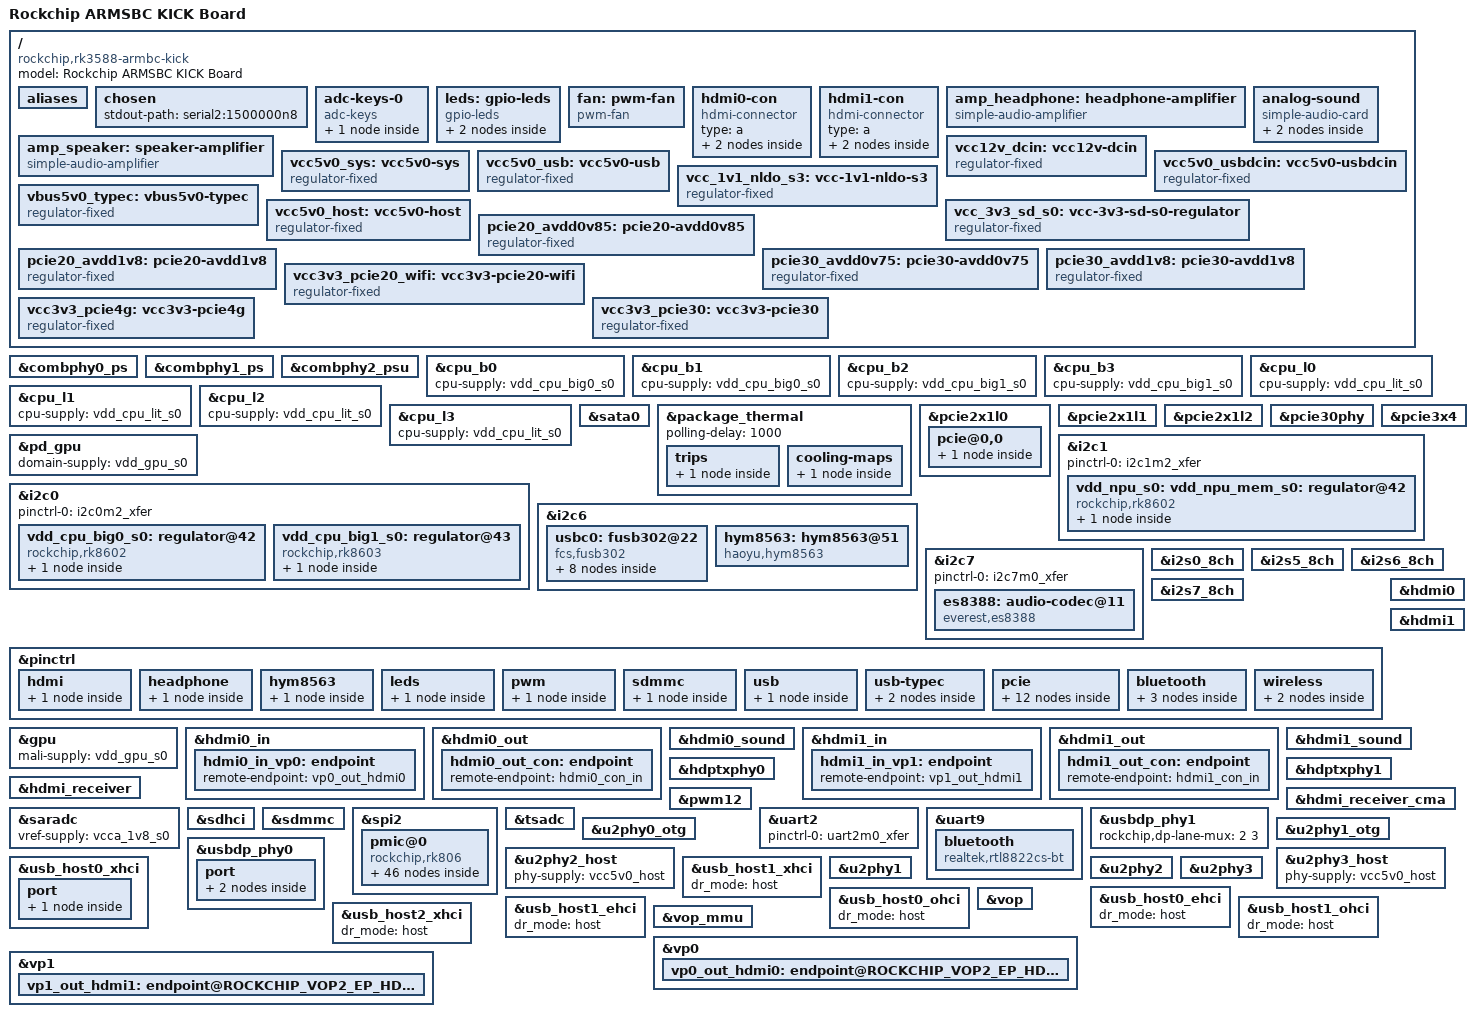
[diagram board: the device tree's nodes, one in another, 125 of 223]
// SPDX-License-Identifier: (GPL-2.0+ OR MIT)
/*
 * Copyright (c) 2024 Rockchip Electronics Co., Ltd.
 *
 */

/dts-v1/;

#include <dt-bindings/gpio/gpio.h>
#include <dt-bindings/input/input.h>
#include <dt-bindings/pinctrl/rockchip.h>
#include <dt-bindings/soc/rockchip,vop2.h>
#include <dt-bindings/usb/pd.h>
#include "rk3588.dtsi"

/ {
	model = "Rockchip ARMSBC KICK Board";
	compatible = "rockchip,rk3588-armbc-kick", "rockchip,rk3588";

	aliases {
		mmc0 = &sdhci;
		mmc1 = &sdmmc;
	};

	chosen {
		stdout-path = "serial2:1500000n8";
	};
	
	adc-keys-0 {
		compatible = "adc-keys";
		io-channels = <&saradc 1>;
		io-channel-names = "buttons";
		keyup-threshold-microvolt = <1800000>;
		poll-interval = <100>;

		button-recovery {
			label = "Recovery";
			linux,code = <KEY_VENDOR>;
			press-threshold-microvolt = <2000>;
		};
	};
	
	leds: gpio-leds {
		compatible = "gpio-leds";
		pinctrl-names = "default";
		status = "okay";
 
		system_led@1 {
			gpios = <&gpio3 RK_PB7 GPIO_ACTIVE_HIGH>;
			linux,default-trigger = "heartbeat";
			linux,default-trigger-delay-ms = <0>;
		};
		
		work_led {
			gpios = <&gpio1 RK_PA4 GPIO_ACTIVE_HIGH>;
			pinctrl-0 = <&work_leds_gpio>;
			default-state = "on";
		};
	};
	
	fan: pwm-fan {
		compatible = "pwm-fan";
		cooling-levels = <0 80 160 255>; // Simple 3-level control
		fan-supply = <&vcc5v0_sys>;      // Replace with correct regulator if needed
		pwms = <&pwm12 0 50000 0>;       // 50 kHz, active high
		#cooling-cells = <2>;
		pinctrl-names = "default";
		pinctrl-0 = <&pwm12_pins>;
	};

	hdmi0-con {
		compatible = "hdmi-connector";
		type = "a";

		port {
			hdmi0_con_in: endpoint {
				remote-endpoint = <&hdmi0_out_con>;
			};
		};
	};

	hdmi1-con {
		compatible = "hdmi-connector";
		type = "a";

		port {
			hdmi1_con_in: endpoint {
				remote-endpoint = <&hdmi1_out_con>;
			};
		};
	};

	
	amp_headphone: headphone-amplifier {
		compatible = "simple-audio-amplifier";
		enable-gpios = <&gpio2 RK_PB3 GPIO_ACTIVE_HIGH>;
		pinctrl-names = "default";
		//pinctrl-0 = <&headphone_amplifier_en>;
		sound-name-prefix = "Headphones Amplifier";
	};

	amp_speaker: speaker-amplifier {
		compatible = "simple-audio-amplifier";
		enable-gpios = <&gpio2 RK_PB2 GPIO_ACTIVE_HIGH>;
		pinctrl-names = "default";
		//pinctrl-0 = <&speaker_amplifier_en>;
		sound-name-prefix = "Speaker Amplifier";
	};
	
	analog-sound {
		compatible = "simple-audio-card";
		pinctrl-names = "default";
		pinctrl-0 = <&hp_detect>;
		simple-audio-card,name = "RK3588 EVB1 Audio";
		simple-audio-card,aux-devs = <&amp_headphone>, <&amp_speaker>;
		simple-audio-card,bitclock-master = <&masterdai>;
		simple-audio-card,format = "i2s";
		simple-audio-card,frame-master = <&masterdai>;
		simple-audio-card,hp-det-gpios = <&gpio1 RK_PD5 GPIO_ACTIVE_LOW>;
		simple-audio-card,mclk-fs = <256>;
		simple-audio-card,pin-switches = "Headphones", "Speaker";
		simple-audio-card,routing =
			"Speaker Amplifier INL", "LOUT2",
			"Speaker Amplifier INR", "ROUT2",
			"Speaker", "Speaker Amplifier OUTL",
			"Speaker", "Speaker Amplifier OUTR",
			"Headphones Amplifier INL", "LOUT1",
			"Headphones Amplifier INR", "ROUT1",
			"Headphones", "Headphones Amplifier OUTL",
			"Headphones", "Headphones Amplifier OUTR",
			"LINPUT1", "Onboard Microphone",
			"RINPUT1", "Onboard Microphone",
			"LINPUT2", "Microphone Jack",
			"RINPUT2", "Microphone Jack";
		simple-audio-card,widgets =
			"Microphone", "Microphone Jack",
			"Microphone", "Onboard Microphone",
			"Headphone", "Headphones",
			"Speaker", "Speaker";

		simple-audio-card,cpu {
			sound-dai = <&i2s0_8ch>;
		};

		masterdai: simple-audio-card,codec {
			sound-dai = <&es8388>;		
		};
	};
		
	vcc12v_dcin: vcc12v-dcin {
		compatible = "regulator-fixed";
		regulator-name = "vcc12v_dcin";
		regulator-always-on;
		regulator-boot-on;
		regulator-min-microvolt = <12000000>;
		regulator-max-microvolt = <12000000>;
	};

	vcc5v0_sys: vcc5v0-sys {
		compatible = "regulator-fixed";
		regulator-name = "vcc5v0_sys";
		regulator-always-on;
		regulator-boot-on;
		regulator-min-microvolt = <5000000>;
		regulator-max-microvolt = <5000000>;
		vin-supply = <&vcc12v_dcin>;
	};

	vcc5v0_usbdcin: vcc5v0-usbdcin {
		compatible = "regulator-fixed";
		regulator-name = "vcc5v0_usbdcin";
		regulator-always-on;
		regulator-boot-on;
		regulator-min-microvolt = <5000000>;
		regulator-max-microvolt = <5000000>;
		vin-supply = <&vcc12v_dcin>;
	};

	vcc5v0_usb: vcc5v0-usb {
		compatible = "regulator-fixed";
		regulator-name = "vcc5v0_usb";
		regulator-always-on;
		regulator-boot-on;
		regulator-min-microvolt = <5000000>;
		regulator-max-microvolt = <5000000>;
		vin-supply = <&vcc5v0_usbdcin>;
	};
	
	vcc_1v1_nldo_s3: vcc-1v1-nldo-s3 {
		compatible = "regulator-fixed";
		regulator-name = "vcc_1v1_nldo_s3";
		regulator-always-on;
		regulator-boot-on;
		regulator-min-microvolt = <1100000>;
		regulator-max-microvolt = <1100000>;
		vin-supply = <&vcc5v0_sys>;
	};

	vbus5v0_typec: vbus5v0-typec {
		compatible = "regulator-fixed";
		regulator-name = "vbus5v0_typec";
		regulator-min-microvolt = <5000000>;
		regulator-max-microvolt = <5000000>;
		enable-active-high;
		gpio = <&gpio3 RK_PB0 GPIO_ACTIVE_HIGH>;
		vin-supply = <&vcc5v0_usb>;
		pinctrl-names = "default";
		pinctrl-0 = <&typec5v_pwren>;
	};

	vcc5v0_host: vcc5v0-host {
		compatible = "regulator-fixed";
		regulator-name = "vcc5v0_host";
		regulator-boot-on;
		regulator-always-on;
		regulator-min-microvolt = <5000000>;
		regulator-max-microvolt = <5000000>;
		enable-active-high;
		gpio = <&gpio3 RK_PA4 GPIO_ACTIVE_HIGH>;
		vin-supply = <&vcc5v0_usb>;
		pinctrl-names = "default";
		pinctrl-0 = <&vcc5v0_host_en>;
	};

	vcc_3v3_sd_s0: vcc-3v3-sd-s0-regulator {
		compatible = "regulator-fixed";
		regulator-name = "vcc_3v3_sd_s0";
		#regulator-boot-on;
		#regulator-always-on;
		gpio = <&gpio0 RK_PB7 GPIO_ACTIVE_HIGH>;  
		enable-active-high;
		pinctrl-names = "default";
		pinctrl-0 = <&sd_s0_pwr>;
	};
	
	pcie20_avdd0v85: pcie20-avdd0v85 {
		compatible = "regulator-fixed";
		regulator-name = "pcie20_avdd0v85";
		regulator-boot-on;
		regulator-always-on;
		regulator-min-microvolt = <850000>;
		regulator-max-microvolt = <850000>;
		vin-supply = <&vdda_0v85_s0>;
	};

	pcie20_avdd1v8: pcie20-avdd1v8 {
		compatible = "regulator-fixed";
		regulator-name = "pcie20_avdd1v8";
		regulator-boot-on;
		regulator-always-on;
		regulator-min-microvolt = <1800000>;
		regulator-max-microvolt = <1800000>;
		vin-supply = <&vcca_1v8_s0>;
	};

	pcie30_avdd0v75: pcie30-avdd0v75 {
		compatible = "regulator-fixed";
		regulator-name = "pcie30_avdd0v75";
		regulator-boot-on;
		regulator-always-on;
		regulator-min-microvolt = <750000>;
		regulator-max-microvolt = <750000>;
		vin-supply = <&vdda_0v75_s0>;
	};

	pcie30_avdd1v8: pcie30-avdd1v8 {
		compatible = "regulator-fixed";
		regulator-name = "pcie30_avdd1v8";
		regulator-boot-on;
		regulator-always-on;
		regulator-min-microvolt = <1800000>;
		regulator-max-microvolt = <1800000>;
		vin-supply = <&vcca_1v8_s0>;
	};

	vcc3v3_pcie20_wifi: vcc3v3-pcie20-wifi {
		compatible = "regulator-fixed";
		regulator-name = "vcc3v3_pcie20_wifi";
		regulator-min-microvolt = <3300000>;
		regulator-max-microvolt = <3300000>;
		gpios = <&gpio0 RK_PC4 GPIO_ACTIVE_HIGH>;
		enable-active-high;
		pinctrl-0 = <&wifi_power_en>;
		startup-delay-us = <5000>;
		vin-supply = <&vcc12v_dcin>;
	};

	vcc3v3_pcie4g: vcc3v3-pcie4g {
		compatible = "regulator-fixed";
		regulator-name = "vcc3v3_pcie4g";
		regulator-min-microvolt = <3300000>;
		regulator-max-microvolt = <3300000>;
		enable-active-high;
		gpios = <&gpio2 RK_PC5 GPIO_ACTIVE_HIGH>;
		vin-supply = <&vcc12v_dcin>;
		regulator-boot-on;
		regulator-always-on;
	};

	vcc3v3_pcie30: vcc3v3-pcie30 {
		compatible = "regulator-fixed";
		regulator-name = "vcc3v3_pcie30";
		regulator-min-microvolt = <3300000>;
		regulator-max-microvolt = <3300000>;
		enable-active-high;
		startup-delay-us = <5000>;
		vin-supply = <&vcc12v_dcin>;
	};
};

&combphy0_ps {
	status = "okay";
};

&combphy1_ps {
	status = "okay";
};

&combphy2_psu {
	status = "okay";
};

&cpu_b0 {
	cpu-supply = <&vdd_cpu_big0_s0>;
};

&cpu_b1 {
	cpu-supply = <&vdd_cpu_big0_s0>;
};

&cpu_b2 {
	cpu-supply = <&vdd_cpu_big1_s0>;
};

&cpu_b3 {
	cpu-supply = <&vdd_cpu_big1_s0>;
};

&cpu_l0 {
	cpu-supply = <&vdd_cpu_lit_s0>;
};

&cpu_l1 {
	cpu-supply = <&vdd_cpu_lit_s0>;
};

&cpu_l2 {
	cpu-supply = <&vdd_cpu_lit_s0>;
};

&cpu_l3 {
	cpu-supply = <&vdd_cpu_lit_s0>;
};

&sata0 {
	status = "okay";
};

&package_thermal {
    polling-delay = <1000>;

    trips {
        cpu_fan_trip: cpu-fan-trip {
            temperature = <60000>;   // 60°C
            hysteresis = <2000>;
            type = "active";
        };
    };

    cooling-maps {
        map0 {
            trip = <&cpu_fan_trip>;
            cooling-device = <&fan 0 2>;  // Fan duty levels (0–2 from your cooling-levels)
        };
    };
};

&pcie2x1l0 {
        reset-gpios = <&gpio4 RK_PA5 GPIO_ACTIVE_HIGH>;
        pinctrl-names = "default";
        vpcie3v3-supply = <&vcc3v3_pcie20_wifi>;
        pinctrl-0 = <&pcie2x1l0_reset>, <&pcie2x1l0_wake>, <&pcie2x1l0_clk>, <&wifi_host_wake_irq>;
        rockchip,skip-scan-in-resume;
        rockchip,perst-inactive-ms = <500>;
        status = "okay";
        
	pcie@0,0 {
		reg = <0x200000 0 0 0 0>;
		#address-cells = <3>;
		#size-cells = <2>;
		ranges;
		device_type = "pci";
		bus-range = <0x20 0x2f>;

		wifi: wifi@0,0 {
			compatible = "pci14e4,449d";
			reg = <0x210000 0 0 0 0>;
			clocks = <&hym8563>;
			clock-names = "lpo";
		};
	};
};

&pcie2x1l1 {
	reset-gpios = <&gpio4 RK_PA2 GPIO_ACTIVE_HIGH>;
	pinctrl-names = "default";
	pinctrl-0 = <&pcie2x1l1_reset>, <&pcie2x1l1_clk>, <&pcie2x1l1_wake>;
	status = "okay";
};

&pcie2x1l2 {
	reset-gpios = <&gpio4 RK_PB0 GPIO_ACTIVE_HIGH>;
	pinctrl-names = "default";
	pinctrl-0 = <&pcie2x1l2_reset>, <&pcie2x1l2_clk>, <&pcie2x1l2_wake>;
	status = "okay";
};

&pcie30phy {
	status = "okay";
};

&pcie3x4 {
	reset-gpios = <&gpio4 RK_PB6 GPIO_ACTIVE_HIGH>;
	vpcie3v3-supply = <&vcc3v3_pcie30>;
	pinctrl-names = "default";
	pinctrl-0 = <&pcie30x4_clk>, <&pcie30x4_reset>, <&pcie30x4_wake>;
	status = "okay";
};

&pd_gpu {
	domain-supply = <&vdd_gpu_s0>;
	status = "okay";
};

&i2c0 {
	pinctrl-names = "default";
	pinctrl-0 = <&i2c0m2_xfer>;
	status = "okay";

	vdd_cpu_big0_s0: regulator@42 {
		compatible = "rockchip,rk8602";
		reg = <0x42>;
		fcs,suspend-voltage-selector = <1>;
		regulator-name = "vdd_cpu_big0_s0";
		regulator-always-on;
		regulator-boot-on;
		regulator-min-microvolt = <550000>;
		regulator-max-microvolt = <1050000>;
		regulator-ramp-delay = <2300>;
		vin-supply = <&vcc5v0_sys>;

		regulator-state-mem {
			regulator-off-in-suspend;
		};
	};

	vdd_cpu_big1_s0: regulator@43 {
		compatible = "rockchip,rk8603", "rockchip,rk8602";
		reg = <0x43>;
		fcs,suspend-voltage-selector = <1>;
		regulator-name = "vdd_cpu_big1_s0";
		regulator-always-on;
		regulator-boot-on;
		regulator-min-microvolt = <550000>;
		regulator-max-microvolt = <1050000>;
		regulator-ramp-delay = <2300>;
		vin-supply = <&vcc5v0_sys>;

		regulator-state-mem {
			regulator-off-in-suspend;
		};
	};
};

&i2c1 {
	pinctrl-names = "default";
	pinctrl-0 = <&i2c1m2_xfer>;
	status = "okay";

	vdd_npu_s0: vdd_npu_mem_s0: regulator@42 {
		compatible = "rockchip,rk8602";
		reg = <0x42>;
		fcs,suspend-voltage-selector = <1>;
		regulator-always-on;
		regulator-boot-on;
		regulator-min-microvolt = <550000>;
		regulator-max-microvolt = <950000>;
		regulator-name = "vdd_npu_s0";
		regulator-ramp-delay = <2300>;
		vin-supply = <&vcc5v0_sys>;

		regulator-state-mem {
			regulator-off-in-suspend;
		};
	};
};

&i2c6 {
	status = "okay";

	usbc0: fusb302@22 {
		compatible = "fcs,fusb302";
		reg = <0x22>;
		interrupt-parent = <&gpio0>;
		interrupts = <RK_PD3 IRQ_TYPE_LEVEL_LOW>;
		pinctrl-names = "default";
		pinctrl-0 = <&usbc0_int>;
		vbus-supply = <&vbus5v0_typec>;
		status = "okay";

		usb_con: connector {
			compatible = "usb-c-connector";
			label = "USB-C";
			data-role = "dual";
			op-sink-microwatt = <1000000>;
			power-role = "dual";
			sink-pdos =
				<PDO_FIXED(5000, 1000, PDO_FIXED_USB_COMM)>;
			source-pdos =
				<PDO_FIXED(5000, 3000, PDO_FIXED_USB_COMM)>;
			try-power-role = "source";

			ports {
				#address-cells = <1>;
				#size-cells = <0>;

				port@0 {
					reg = <0>;

					usbc0_orien_sw: endpoint {
						remote-endpoint = <&usbdp_phy0_orientation_switch>;
					};
				};

				port@1 {
					reg = <1>;

					usbc0_role_sw: endpoint {
						remote-endpoint = <&dwc3_0_role_switch>;
					};
				};

				port@2 {
					reg = <2>;

					dp_altmode_mux: endpoint {
						remote-endpoint = <&usbdp_phy0_dp_altmode_mux>;
					};
				};
			};
		};
	};

	hym8563: hym8563@51 {
		compatible = "haoyu,hym8563";
		reg = <0x51>;
		#clock-cells = <0>;
		clock-frequency = <32768>;
		clock-output-names = "hym8563";
		pinctrl-names = "default";
		pinctrl-0 = <&hym8563_int>;
		interrupt-parent = <&gpio0>;
		interrupts = <RK_PB0 IRQ_TYPE_LEVEL_LOW>;
		wakeup-source;
	};
};

&i2c7 {
	status = "okay";
	pinctrl-0 = <&i2c7m0_xfer>;
	es8388: audio-codec@11 {
		compatible = "everest,es8388", "everest,es8328";
		reg = <0x11>;
		clocks = <&cru I2S0_8CH_MCLKOUT>;
		assigned-clocks = <&cru I2S0_8CH_MCLKOUT>;
		assigned-clock-rates = <12288000>;
		AVDD-supply = <&vcc_1v8_s0>;
		DVDD-supply = <&vcc_1v8_s0>;
		HPVDD-supply = <&vcca_3v3_s0>;
		PVDD-supply = <&vcca_3v3_s0>;
		#sound-dai-cells = <0>;
	};
};

&i2s0_8ch {
	pinctrl-0 = <&i2s0_lrck
		     &i2s0_mclk
		     &i2s0_sclk
		     &i2s0_sdi0
		     &i2s0_sdo0>;
	status = "okay";
};

&i2s5_8ch {
	status = "okay";
};

&i2s6_8ch {
	status = "okay";
};

&i2s7_8ch {
	status = "okay";
};
	
&pinctrl {

	hdmi {
		hdmirx_det: hdmirx-det {
			rockchip,pins = <1 RK_PD5 RK_FUNC_GPIO &pcfg_pull_up>;
		};
	};

	headphone {
		hp_detect: hp-detect {
			rockchip,pins = <1 RK_PC4 RK_FUNC_GPIO &pcfg_pull_none>;
		};
	};

	hym8563 {
		hym8563_int: hym8563-int {
			rockchip,pins = <0 RK_PB0 RK_FUNC_GPIO &pcfg_pull_up>;
		};
	};

	leds {
		work_leds_gpio: work-leds-gpio {
			rockchip,pins = <1 RK_PA4 RK_FUNC_GPIO &pcfg_pull_down>;
		};
	};
	
	pwm {
		pwm12_pins: pwm12-pins {
    		rockchip,pins = <4 RK_PC2 RK_FUNC_GPIO &pcfg_pull_none>; 
		};
	};
	
	sdmmc {
		sd_s0_pwr: sd-s0-pwr {
			rockchip,pins = <0 RK_PB7 RK_FUNC_GPIO &pcfg_pull_up>;
		};
	};

	usb {
		vcc5v0_host_en: vcc5v0-host-en {
			rockchip,pins = <3 RK_PA4 RK_FUNC_GPIO &pcfg_pull_none>;
		};
	};

	usb-typec {
		usbc0_int: usbc0-int {
			rockchip,pins = <0 RK_PD3 RK_FUNC_GPIO &pcfg_pull_up>;
		};

		typec5v_pwren: typec5v-pwren {
			rockchip,pins = <3 RK_PB0 RK_FUNC_GPIO &pcfg_pull_none>;
		};
	};

	pcie {
		pcie30x4_clk: pcie30x4-clk {
			rockchip,pins = <4 RK_PB4 RK_FUNC_GPIO &pcfg_output_low>;
			};
			
		pcie30x4_reset: pcie30x4-reset {
			rockchip,pins = <4 RK_PB3 RK_FUNC_GPIO &pcfg_output_low>;
			};
		
		pcie30x4_wake: pcie30x4-wake {
			rockchip,pins = <4 RK_PB5 RK_FUNC_GPIO &pcfg_output_low>;
			};	
		
		pcie2x1l0_reset: pcie2x1l0-reset {
			rockchip,pins = <4 RK_PA5 RK_FUNC_GPIO &pcfg_pull_none>;
		};
		
		pcie2x1l0_clk:  pcie2x1l0-clk {
			rockchip,pins = <4 RK_PA3 RK_FUNC_GPIO &pcfg_pull_none>;
		};
		
		pcie2x1l0_wake: pcie2x1l0-wake {
			rockchip,pins = <4 RK_PA4 RK_FUNC_GPIO &pcfg_pull_none>;
		};
		
		pcie2x1l1_reset: cie2x1l1-reset {
			rockchip,pins = <4 RK_PA2 RK_FUNC_GPIO &pcfg_pull_none>;
		};
		
		pcie2x1l1_clk:  pcie2x1l1-clk {
			rockchip,pins = <4 RK_PA0 RK_FUNC_GPIO &pcfg_pull_none>;
		};
		
		pcie2x1l1_wake: pcie2x1l1-wake {
			rockchip,pins = <4 RK_PA1 RK_FUNC_GPIO &pcfg_pull_none>;
		};
		
		pcie2x1l2_reset: cie2x1l2-reset {
			rockchip,pins = <4 RK_PB0 RK_FUNC_GPIO &pcfg_pull_none>;
		};
		
		pcie2x1l2_clk: pcie2x1l2-clk {
			rockchip,pins = <4 RK_PA6 RK_FUNC_GPIO &pcfg_pull_none>;
		};
		
		pcie2x1l2_wake: pcie2x1l2-wake {
			rockchip,pins = <4 RK_PA7 RK_FUNC_GPIO &pcfg_pull_none>;
		};
	};
	
    bluetooth {

		bt_reset_gpio: bt-reset-gpio {
			rockchip,pins = <0 RK_PC6 RK_FUNC_GPIO &pcfg_pull_none>;
		};

		bt_wake_gpio: bt-wake-gpio {
			rockchip,pins = <0 RK_PC5 RK_FUNC_GPIO &pcfg_pull_none>;
		};

		bt_irq_gpio: bt-irq-gpio {
			rockchip,pins = <0 RK_PA0 RK_FUNC_GPIO &pcfg_pull_none>;
		};
	};
	
	wireless {
		wifi_host_wake_irq: wifi-host-wake-irq {
			rockchip,pins = <0 RK_PB2 RK_FUNC_GPIO &pcfg_pull_down>;
		};
	
		wifi_power_en: wifi-power_en {
			rockchip,pins = <0 RK_PC4 RK_FUNC_GPIO &pcfg_pull_up>;
    		};
    	};

};


&gpu {
	mali-supply = <&vdd_gpu_s0>;
	status = "okay";
};

&hdmi0 {
	status = "okay";
};

&hdmi0_in {
	hdmi0_in_vp0: endpoint {
		remote-endpoint = <&vp0_out_hdmi0>;
	};
};

&hdmi0_out {
	hdmi0_out_con: endpoint {
		remote-endpoint = <&hdmi0_con_in>;
	};
};

&hdmi0_sound {
	status = "okay";	
};

&hdmi1 {
	status = "okay";
};

&hdmi1_in {
	hdmi1_in_vp1: endpoint {
		remote-endpoint = <&vp1_out_hdmi1>;
	};
};

&hdmi1_out {
	hdmi1_out_con: endpoint {
		remote-endpoint = <&hdmi1_con_in>;
	};
};

&hdmi1_sound {
	status = "okay";
};

&hdptxphy0 {
	status = "okay";
};

&hdptxphy1 {
	status = "okay";
};

&hdmi_receiver_cma {
	status = "okay";
};

&hdmi_receiver {
	status = "okay";
	hpd-gpios = <&gpio1 RK_PD5 GPIO_ACTIVE_LOW>;
	pinctrl-0 = <&hdmim1_rx_cec &hdmim1_rx_hpdin &hdmim1_rx_scl &hdmim1_rx_sda &hdmirx_det>;
	pinctrl-names = "default";
	memory-region = <&hdmi_receiver_cma>;
	
};

&pwm12 {
	status = "okay";
};

&saradc {
	vref-supply = <&vcca_1v8_s0>;
	status = "okay";
};

&sdhci {
	bus-width = <8>;
	mmc-hs400-1_8v;
	mmc-hs400-enhanced-strobe;
	no-sdio;
	no-sd;
	non-removable;
	status = "okay";
};

&sdmmc {
    status = "okay";
    bus-width = <4>;
    cap-sd-highspeed;
    cd-gpios = <&gpio0 RK_PA4 GPIO_ACTIVE_LOW>;
    disable-wp;
    max-frequency = <200000000>;
    no-sdio;
    no-mmc;
    sd-uhs-sdr12;
	sd-uhs-sdr25;
	sd-uhs-sdr50;
	sd-uhs-ddr50;
	sd-uhs-sdr104;
  	vmmc-supply = <&vcc_3v3_sd_s0>;
	vqmmc-supply = <&vccio_sd_s0>;   
    pinctrl-names = "default";
    pinctrl-0 = <&sdmmc_clk &sdmmc_cmd &sdmmc_det &sdmmc_bus4>;
};

&spi2 {
	status = "okay";
	assigned-clocks = <&cru CLK_SPI2>;
	assigned-clock-rates = <200000000>;
	pinctrl-names = "default";
	pinctrl-0 = <&spi2m2_cs0 &spi2m2_pins>;
	num-cs = <1>;

	pmic@0 {
		compatible = "rockchip,rk806";
		reg = <0x0>;
		interrupt-parent = <&gpio0>;
		interrupts = <7 IRQ_TYPE_LEVEL_LOW>;
		gpio-controller;
		#gpio-cells = <2>;
		pinctrl-names = "default";
		pinctrl-0 = <&pmic_pins>, <&rk806_dvs1_null>,
			    <&rk806_dvs2_null>, <&rk806_dvs3_null>;
		spi-max-frequency = <1000000>;
		system-power-controller;
		vcc1-supply = <&vcc5v0_sys>;
		vcc2-supply = <&vcc5v0_sys>;
		vcc3-supply = <&vcc5v0_sys>;
		vcc4-supply = <&vcc5v0_sys>;
		vcc5-supply = <&vcc5v0_sys>;
		vcc6-supply = <&vcc5v0_sys>;
		vcc7-supply = <&vcc5v0_sys>;
		vcc8-supply = <&vcc5v0_sys>;
		vcc9-supply = <&vcc5v0_sys>;
		vcc10-supply = <&vcc5v0_sys>;
		vcc11-supply = <&vcc_2v0_pldo_s3>;
		vcc12-supply = <&vcc5v0_sys>;
		vcc13-supply = <&vcc_1v1_nldo_s3>;
		vcc14-supply = <&vcc_1v1_nldo_s3>;
		vcca-supply = <&vcc5v0_sys>;

		rk806_dvs1_null: dvs1-null-pins {
			pins = "gpio_pwrctrl1";
			function = "pin_fun0";
		};

		rk806_dvs2_null: dvs2-null-pins {
			pins = "gpio_pwrctrl2";
			function = "pin_fun0";
		};

		rk806_dvs3_null: dvs3-null-pins {
			pins = "gpio_pwrctrl3";
			function = "pin_fun0";
		};

		regulators {
			vdd_gpu_s0: dcdc-reg1 {
				regulator-boot-on;
				regulator-min-microvolt = <550000>;
				regulator-max-microvolt = <950000>;
				regulator-ramp-delay = <12500>;
				regulator-name = "vdd_gpu_s0";
				regulator-enable-ramp-delay = <400>;

				regulator-state-mem {
					regulator-off-in-suspend;
				};
			};

			vdd_cpu_lit_s0: dcdc-reg2 {
				regulator-name = "vdd_cpu_lit_s0";
				regulator-always-on;
				regulator-boot-on;
				regulator-min-microvolt = <550000>;
				regulator-max-microvolt = <950000>;
				regulator-ramp-delay = <12500>;

				regulator-state-mem {
					regulator-off-in-suspend;
				};
			};

			vdd_log_s0: dcdc-reg3 {
				regulator-name = "vdd_log_s0";
				regulator-always-on;
				regulator-boot-on;
				regulator-min-microvolt = <675000>;
				regulator-max-microvolt = <750000>;
				regulator-ramp-delay = <12500>;

				regulator-state-mem {
					regulator-off-in-suspend;
					regulator-suspend-microvolt = <750000>;
				};
			};

			vdd_vdenc_s0: dcdc-reg4 {
				regulator-name = "vdd_vdenc_s0";
				regulator-always-on;
				regulator-boot-on;
				regulator-min-microvolt = <550000>;
				regulator-max-microvolt = <950000>;
				regulator-ramp-delay = <12500>;

				regulator-state-mem {
					regulator-off-in-suspend;
				};
			};

			vdd_ddr_s0: dcdc-reg5 {
				regulator-name = "vdd_ddr_s0";
				regulator-always-on;
				regulator-boot-on;
				regulator-min-microvolt = <675000>;
				regulator-max-microvolt = <900000>;
				regulator-ramp-delay = <12500>;

				regulator-state-mem {
					regulator-off-in-suspend;
					regulator-suspend-microvolt = <850000>;
				};
			};

			vdd2_ddr_s3: dcdc-reg6 {
				regulator-name = "vdd2_ddr_s3";
				regulator-always-on;
				regulator-boot-on;

				regulator-state-mem {
					regulator-on-in-suspend;
				};
			};

			vcc_2v0_pldo_s3: dcdc-reg7 {
				regulator-name = "vdd_2v0_pldo_s3";
				regulator-always-on;
				regulator-boot-on;
				regulator-min-microvolt = <2000000>;
				regulator-max-microvolt = <2000000>;
				regulator-ramp-delay = <12500>;

				regulator-state-mem {
					regulator-on-in-suspend;
					regulator-suspend-microvolt = <2000000>;
				};
			};

			vcc_3v3_s3: dcdc-reg8 {
				regulator-name = "vcc_3v3_s3";
				regulator-always-on;
				regulator-boot-on;
				regulator-min-microvolt = <3300000>;
				regulator-max-microvolt = <3300000>;

				regulator-state-mem {
					regulator-on-in-suspend;
					regulator-suspend-microvolt = <3300000>;
				};
			};

			vddq_ddr_s0: dcdc-reg9 {
				regulator-name = "vddq_ddr_s0";
				regulator-always-on;
				regulator-boot-on;

				regulator-state-mem {
					regulator-off-in-suspend;
				};
			};

			vcc_1v8_s3: dcdc-reg10 {
				regulator-name = "vcc_1v8_s3";
				regulator-always-on;
				regulator-boot-on;
				regulator-min-microvolt = <1800000>;
				regulator-max-microvolt = <1800000>;

				regulator-state-mem {
					regulator-on-in-suspend;
					regulator-suspend-microvolt = <1800000>;
				};
			};

			vcca_1v8_s0: pldo-reg1 {
				regulator-name = "vcca_1v8_s0";
				regulator-always-on;
				regulator-boot-on;
				regulator-min-microvolt = <1800000>;
				regulator-max-microvolt = <1800000>;

				regulator-state-mem {
					regulator-off-in-suspend;
				};
			};

			vcc_1v8_s0: pldo-reg2 {
				regulator-name = "vcc_1v8_s0";
				regulator-always-on;
				regulator-boot-on;
				regulator-min-microvolt = <1800000>;
				regulator-max-microvolt = <1800000>;

				regulator-state-mem {
					regulator-off-in-suspend;
					regulator-suspend-microvolt = <1800000>;
				};
			};

			vdda_1v2_s0: pldo-reg3 {
				regulator-name = "vdda_1v2_s0";
				regulator-always-on;
				regulator-boot-on;
				regulator-min-microvolt = <1200000>;
				regulator-max-microvolt = <1200000>;

				regulator-state-mem {
					regulator-off-in-suspend;
				};
			};

			vcca_3v3_s0: pldo-reg4 {
				regulator-name = "vcca_3v3_s0";
				regulator-always-on;
				regulator-boot-on;
				regulator-min-microvolt = <3300000>;
				regulator-max-microvolt = <3300000>;
				regulator-ramp-delay = <12500>;

				regulator-state-mem {
					regulator-off-in-suspend;
				};
			};

			vccio_sd_s0: pldo-reg5 {
				regulator-name = "vccio_sd_s0";
				regulator-always-on;
				regulator-boot-on;
				regulator-min-microvolt = <1800000>;
				regulator-max-microvolt = <3300000>;
				regulator-ramp-delay = <12500>;

				regulator-state-mem {
					regulator-off-in-suspend;
				};
			};

			pldo6_s3: pldo-reg6 {
				regulator-name = "pldo6_s3";
				regulator-always-on;
				regulator-boot-on;
				regulator-min-microvolt = <1800000>;
				regulator-max-microvolt = <1800000>;

				regulator-state-mem {
					regulator-on-in-suspend;
					regulator-suspend-microvolt = <1800000>;
				};
			};

			vdd_0v75_s3: nldo-reg1 {
				regulator-name = "vdd_0v75_s3";
				regulator-always-on;
				regulator-boot-on;
				regulator-min-microvolt = <750000>;
				regulator-max-microvolt = <750000>;

				regulator-state-mem {
					regulator-on-in-suspend;
					regulator-suspend-microvolt = <750000>;
				};
			};

			vdda_ddr_pll_s0: nldo-reg2 {
				regulator-name = "vdda_ddr_pll_s0";
				regulator-always-on;
				regulator-boot-on;
				regulator-min-microvolt = <850000>;
				regulator-max-microvolt = <850000>;

				regulator-state-mem {
					regulator-off-in-suspend;
					regulator-suspend-microvolt = <850000>;
				};
			};

			vdda_0v75_s0: nldo-reg3 {
				regulator-name = "vdda_0v75_s0";
				regulator-always-on;
				regulator-boot-on;
				regulator-min-microvolt = <750000>;
				regulator-max-microvolt = <750000>;

				regulator-state-mem {
					regulator-off-in-suspend;
				};
			};

			vdda_0v85_s0: nldo-reg4 {
				regulator-name = "vdda_0v85_s0";
				regulator-always-on;
				regulator-boot-on;
				regulator-min-microvolt = <850000>;
				regulator-max-microvolt = <850000>;

				regulator-state-mem {
					regulator-off-in-suspend;
				};
			};

			vdd_0v75_s0: nldo-reg5 {
				regulator-name = "vdd_0v75_s0";
				regulator-always-on;
				regulator-boot-on;
				regulator-min-microvolt = <750000>;
				regulator-max-microvolt = <750000>;

				regulator-state-mem {
					regulator-off-in-suspend;
				};
			};
		};
	};
};

&tsadc {
	status = "okay";
};

&uart2 {
	pinctrl-0 = <&uart2m0_xfer>;
	status = "okay";
};

&uart9 {
	pinctrl-names = "default";
	pinctrl-0 = <&uart9m0_xfer>, <&uart9m0_ctsn>, <&uart9m0_rtsn>;
	uart-has-rtscts;
	status = "okay";

	bluetooth {
		compatible = "realtek,rtl8822cs-bt";
		clocks = <&hym8563>;
		clock-names = "ext_clock";
		shutdown-gpios       = <&gpio0 RK_PC6 GPIO_ACTIVE_HIGH>;  // BT_REG_ON_H
		device-wakeup-gpios  = <&gpio0 RK_PA0 GPIO_ACTIVE_HIGH>;  // BT_WAKE
		host-wakeup-gpios    = <&gpio0 RK_PC5 GPIO_ACTIVE_HIGH>;  // HOST_WAKE_BT_H
		vbat-supply = <&vcca_3v3_s0>;
		vddio-supply = <&vcc_1v8_s0>;
		pinctrl-names = "default";
		pinctrl-0 = <&bt_reset_gpio>, <&bt_wake_gpio>, <&bt_irq_gpio>;
		status = "okay";
	};
};

&usbdp_phy1 {
	status = "okay";
};

&u2phy0_otg {
	rockchip,typec-vbus-det;
};

&u2phy1_otg {
	phy-supply = <&vcc5v0_host>;
};

&u2phy2_host {
	phy-supply = <&vcc5v0_host>;
};

&u2phy3_host {
	phy-supply = <&vcc5v0_host>;
};

&usbdp_phy0 {
	mode-switch;
	svid = <0xff01>;
	orientation-switch;
	sbu1-dc-gpios = <&gpio1 RK_PB4 GPIO_ACTIVE_HIGH>;
	sbu2-dc-gpios = <&gpio1 RK_PB5 GPIO_ACTIVE_HIGH>;
	status = "okay";

	port {
		#address-cells = <1>;
		#size-cells = <0>;

		usbdp_phy0_orientation_switch: endpoint@0 {
			reg = <0>;
			remote-endpoint = <&usbc0_orien_sw>;
		};

		usbdp_phy0_dp_altmode_mux: endpoint@1 {
			reg = <1>;
			remote-endpoint = <&dp_altmode_mux>;
		};
	};
};

&usbdp_phy1 {
	rockchip,dp-lane-mux = <2 3>;
};

&usb_host0_xhci {
	dr_mode = "otg";
	usb-role-switch;
	status = "okay";

	port {
		#address-cells = <1>;
		#size-cells = <0>;

		dwc3_0_role_switch: endpoint@0 {
			reg = <0>;
			remote-endpoint = <&usbc0_role_sw>;
		};
	};
};

&usb_host1_xhci {
	dr_mode = "host";
	status = "okay";
};

&u2phy1 {
	status = "okay";
};

&u2phy0_otg {
	dr_mode = "host";
	status = "okay";
};

&u2phy1_otg {
	dr_mode = "host";
	status = "okay";
};

&u2phy2 {
	status = "okay";
};

&u2phy2_host {
	status = "okay";
};

&u2phy3 {
	status = "okay";
};

&u2phy3_host {
	status = "okay";
};

&usb_host0_ehci {
	dr_mode = "host";
	status = "okay";
};

&usb_host0_ohci {
	dr_mode = "host";
	status = "okay";
};

&usb_host0_xhci {
	dr_mode = "host";
	status = "okay";
};

&usb_host1_ehci {
	dr_mode = "host";
	status = "okay";
};

&usb_host1_ohci {
	dr_mode = "host";
	status = "okay";
};

&usb_host1_xhci {
	dr_mode = "host";
	status = "okay";
};

&usb_host2_xhci {
	dr_mode = "host";
	status = "okay";
};

&vop {
	status = "okay";
};

&vop_mmu {
	status = "okay";
};

&vp0 {
	vp0_out_hdmi0: endpoint@ROCKCHIP_VOP2_EP_HDMI0 {
		reg = <ROCKCHIP_VOP2_EP_HDMI0>;
		remote-endpoint = <&hdmi0_in_vp0>;
	};
};

&vp1 {
	vp1_out_hdmi1: endpoint@ROCKCHIP_VOP2_EP_HDMI1 {
		reg = <ROCKCHIP_VOP2_EP_HDMI1>;
		remote-endpoint = <&hdmi1_in_vp1>;
	};
};
